AUTOSAR XML (schema 00046)
package /ComponentTypes
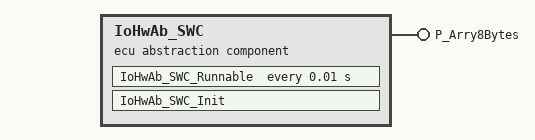
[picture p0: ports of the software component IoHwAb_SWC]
  ecu abstraction sw component type IoHwAb_SWC
    provide port P_Arry8Bytes: nonqueued-sender-com-spec{data-element=DEP_Arry8Bytes, init-value=8 x 0}, provided-interface=P_Arry8Bytes
    behavior IoHwAb_SWC_InternalBehavior
      init event IoHwAb_SWC_InitEvent: start-on-event=IoHwAb_SWC_Init
      timing event TMT_IoHwAb_SWC_Runnable: start-on-event=IoHwAb_SWC_Runnable, period=0.01
      runnable IoHwAb_SWC_Runnable: minimum-start-interval=0.01
        data-send-points:
          access SEND_P_Arry8Bytes_DEP_Arry8Bytes: accessed-variable=P_Arry8Bytes.DEP_Arry8Bytes
      runnable IoHwAb_SWC_Init
  swc implementation IoHwAb_SWC_Implementation: behavior=IoHwAb_SWC_InternalBehavior
